# S32R372 register map
Vendor: Freescale Semiconductor, Inc.; Series: Qorivva; File version: 1.6
Registers are 32-bit, read-write, reset 0x0 unless marked. A register's access mark holds for its fields unless they carry their own. Offsets are from the block's base; [hi:lo] are bit positions; {n}, {i} and the like mark numbered series.

## MIPICSI2 — Camera Serial Interface
Base 0xFBF08000; register names take the prefix MIPICSI2_
0x00 CONC — RX Controller Configuration Register
  [0] NULANE — Number of active lanes being used to receive MIPICSI2 data
    0=1 lane; 1=2 Lanes
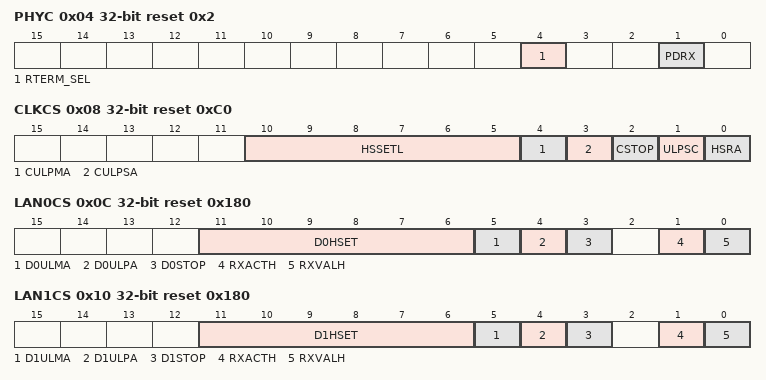
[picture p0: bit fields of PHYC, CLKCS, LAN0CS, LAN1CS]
0x04 PHYC reset 0x2 — PHY Configuration Register
  [4] RTERM_SEL — Voltage Level selection for HS termination
    0=Low Power Receive level enables High Speed Termination; 1=Low Power Contention Detector level enables High Speed Termination
  [1] PDRX — Power Down Receiver
    0=Power down disabled; 1=Power down enabled for all blocks inside PHY
0x08 CLKCS reset 0xC0 — Clock Configuration Status Register
  [10:5] HSSETL — Clock Lane Program RX HS Settle
  [4] CULPMA ro — Clock Lane ULPS mark Active State
    0=Clock Lane not in Mark active state; 1=Clock Lane is in mark active state
  [3] CULPSA ro — Clock Lane ULPS Active
    0=Clock Lane not in ULPS mode; 1=Clock Lane in ULPS mode
  [2] CSTOP ro — Clock Lane Stop State
    0=Clock Lane not in stop state; 1=Clock Lane in stop state
  [1] ULPSC ro — Clock Lane ULPS
    0=Clock lane not in ultra low power state; 1=Clock Lane in ultra low power state
  [0] HSRA ro — High Speed Clock Receive Active
    0=DDR clock not being received on the clock lane currently; 1=Clock lane is receiving DDR clock
0x0C LAN0CS reset 0x180 — D-PHY Lane 0 Configuration Status Register
  [11:6] D0HSET — Data lane 0 Program RX HS Settle time
  [5] D0ULMA ro — Data Lane 0 ULPS Mark Active
    0=Data lane 0 is not in Mark 1 state; 1=Data lane 0 is in mark 1 state
  [4] D0ULPA ro — Data lane 0 ULPS Active
    0=Data Lane 0 ULPS not active; 1=Data lane 0 ULPS Active
  [3] D0STOP ro — Data Lane 0 Stop State
    0=Data lane 0 not in stop state; 1=Data lane 0 in stop state
  [1] RXACTH ro — D-PHY Data lane 0 RX active High Speed data
    0=No High Speed data reception ongoing from the lane interconnect; 1=High speed data reception ongoing from lane interconnect
  [0] RXVALH ro — Data Lane 0 RX Valid HS
    0=No Valid High Speed data being driven from data lane 0 to MIPICSI2 RX controller; 1=Valid High Speed data being driven from data lane 0 to MIPICSI2 RX Controller
0x10 LAN1CS reset 0x180 — D-PHY Data LANE 1 Configuration Status Register
  [11:6] D1HSET — D_PHY Data Lane 1 PRG HS Settle time
  [5] D1ULMA ro — D_PHY Data Lane 1 ULPS Mark active
    0=Data Lane 1 not in ULPS mark active state; 1=Data Lane 1 in ULPS Mark Active state
  [4] D1ULPA ro — D-PHY Data Lane 1 ULPS Active
    0=Data lane not in ULPS state; 1=Data Lane 1 in ULPS state
  [3] D1STOP ro — D-PHY Data Lane 1 Stop
    0=Data lane 1 is not in stop state; 1=Data lane 1 is in stop state
  [1] RXACTH ro — D-PHY Data lane 1 Active HS
    0=Data lane 1 not receiving high speed active data on the lane interconnect; 1=Data Lane 1 receiving active high speed data on the lane interconnect
  [0] RXVALH ro — D-PHY Data lane 1 Receive Valid High speed
    0=No Valid High speed data being driven from data lane 1 to the MIPICSI2 RX controller; 1=Valid HS data being transmitted from data lane 1 to the MIPICSI2 RX controller
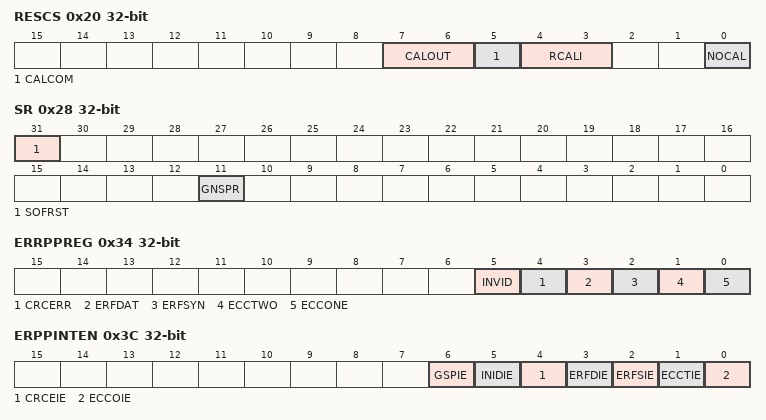
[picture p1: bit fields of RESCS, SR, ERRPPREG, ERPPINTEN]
0x20 RESCS — External Resistor Configuration Status Register
  [7:6] CALOUT ro — Calibrator output
  [5] CALCOM ro — Calibration Complete
    0=Calibration incomplete; 1=Calibration Complete
  [4:3] RCALI — Resistor Calibration Input
  [0] NOCAL — No Calibration
    0=Auto Calibration; 1=No auto Calibration, manual calibration
0x28 SR — Status Register
  [31] SOFRST — Software reset
    0=No soft reset requested; 1=Soft Reset requested by Software. When set it causes a reset of all the registers and all the FIFOs will be flushed.
  [11] GNSPR — Generic Short Packet Received
    0=No generic short packet field was received; 1=Generic Short Packet field was received
0x2C DATAID ro — DataID Report Register
  [5:0] DATIDF — Data ID Field
    0=Frame start; 1=Frame end; 2=Line start; 3=Line end; 16=Null data; 17=Blanking data; 30=YUV 422 - 8bit data; 31=YUV 422 10 bit data; 34=RGB565 data; 36=RGB888 data; 42=RAW8 data; 43=RAW10 data; 44=RAW12 data; 45=RAW14 data; 18=Embedded data
0x34 ERRPPREG — Protocol and Packet Error Register
  [5] INVID — Invalid ID
  [4] CRCERR — CRC Error
  [3] ERFDAT — Frame data error
  [2] ERFSYN — Frame synchronization error
  [1] ECCTWO — ECC Two Bit Error
  [0] ECCONE — ECC one bit error
0x38 ERRPOS ro — Error Position
  [4:0] ERRPOS
0x3C ERPPINTEN — Protocol Packet Error Interrupt Enable
  [6] GSPIE — Generic Short Packet Interrupt Enable
    0=Interrupt on generic short packet reception disabled; 1=Interrupt on generic short packet reception enabled
  [5] INIDIE — Invalid ID Error Interrupt Enable
    0=Interrupt on invalid ID error disabled; 1=Interrupt on Invalid ID error enabled
  [4] CRCEIE — CRC Error Interrupt Enable
    0=Interrupt on CRC error disabled; 1=Interrupt on CRC error enabled
  [3] ERFDIE — Error Frame Data Interrupt Enable
    0=Interrupt on frame data error disabled; 1=Interrupt on frame data error enabled
  [2] ERFSIE — Frame Synchronization Error Interrupt Enable
    0=Interrupt on frame Synchronization error disabled; 1=Interrupt on frame Synchronization error enabled
  [1] ECCTIE — ECC Two Interrupt Enable
    0=Interrupt on ECC two bit error disabled; 1=Interrupt on ECC two bit error enabled
  [0] ECCOIE — ECC One Interrupt Enable
    0=Interrupt on ECC one bit error disabled; 1=Interrupt on ECC one bit error enabled
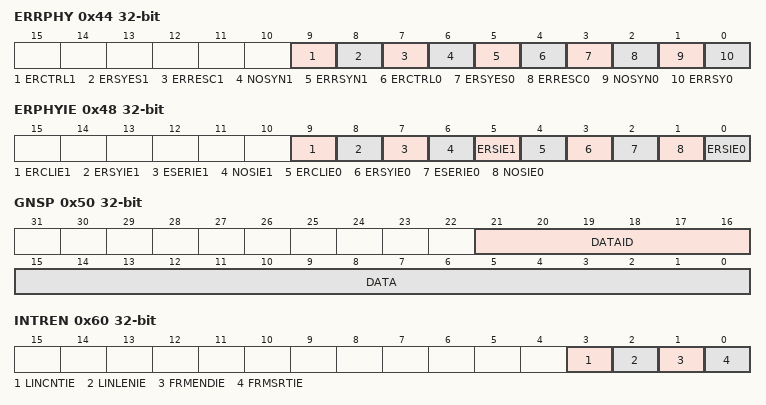
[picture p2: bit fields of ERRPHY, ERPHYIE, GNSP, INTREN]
0x44 ERRPHY — PHY Error Report Register
  [9] ERCTRL1 — Control Error on lane 1
  [8] ERSYES1 — Synchronization error in Escape mode on lane 1
  [7] ERRESC1 — Escape Mode Entry Error on lane 1
  [6] NOSYN1 — No Synchronization Error Lane 1
  [5] ERRSYN1 — Error in the synchronization pattern detected by PHY in lane1
  [4] ERCTRL0 — Control Error on lane 0
  [3] ERSYES0 — Synchronization error in Escape mode on lane 0
  [2] ERRESC0 — Escape Mode Entry Error on lane 0
  [1] NOSYN0 — No Synchronization Error Lane 0 on HS entry
  [0] ERRSY0 — Error in the synchronization pattern detected by PHY in lane0
0x48 ERPHYIE — Phy Error Interrupt Enable Register
  [9] ERCLIE1 — This field allows interrupt to be enabled when an incorrect line state sequence transition has been observed
    0=Interrupt disabled on control errors encountered on lane 3; 1=Interrupt enabled on control errors encountered on lane 3
  [8] ERSYIE1 — This field is used to enable the interrupt when a synchronization error is observed in the escape mode
    0=interrupt disabled on Synchronization errors in escape mode on lane1; 1=interrupt enabled on Synchronization errors in escape mode on lane1
  [7] ESERIE1 — This field is used for enabling interrupt on detection of an escape mode entry error
    0=Interrupt disabled on escape mode entry error on lane 1; 1=Interrupt enabled on escape mode entry error on lane 1
  [6] NOSIE1 — This field enables interrupt generation when the NOSYN1 field in the error register is set
    0=Interrupt disabled on multibit errors in Synchronization error on lane 1; 1=Interrupt enabled on multibit errors in Synchronization error on lane 1
  [5] ERSIE1 — This field enables interrupt generation when the ERSYN1 field in the error register is set
    0=Interrupt on One bit Synchronization error in sync pattern on high speed entry on lane 1 disabled; 1=Interrupt on One bit Synchronization error in sync pattern on high speed entry on lane 1 enabled
  [4] ERCLIE0 — This field allows interrupt to be enabled when an incorrect line state sequence transition has been observed
    0=Interrupt disabled on control errors encountered on lane 0; 1=Interrupt enabled on control errors encountered on lane 0
  [3] ERSYIE0 — This field is used to enable the interrupt when a synchronization error is observed in the escape mode
    0=interrupt disabled on Synchronization errors in escape mode on lane0; 1=interrupt enabled on Synchronization errors in escape mode on lane0
  [2] ESERIE0 — This field is used for enabling interrupt on detection of an escape mode entry error
    0=Interrupt disabled on escape mode entry error; 1=Interrupt enabled on escape mode entry error
  [1] NOSIE0 — This field enables interrupt generation when the NOSYN0 field in the error register is set
    0=Interrupt disabled on multibit errors in Synchronization error on lane 0; 1=Interrupt enabled on multibit errors in Synchronization error on lane 0
  [0] ERSIE0 — This field enables interrupt generation when the ERSYN0 field in the error register is set
    0=Interrupt on One bit Synchronization error in sync pattern on high speed entry on lane 0 disabled; 1=Interrupt on One bit Synchronization error in sync pattern on high speed entry on lane 0 enabled
0x4C RXEN — RX Enable Register
  [0] RXEN — Receive enable
    0=RX disabled; 1=RX enabled
0x50 GNSP ro — Generic Short Packet Data Register
  [21:16] DATAID — Data type
    {v}=Generic short packet code {v-7} (v=8..15)
  [15:0] DATA — Data field of a generic short packet
0x54 INVID ro — Invalid ID Report Register
  [5:0] INVID — Invalid ID
0x58 LINLEN — LINE LENGTH
  [15:0] LINLEN
0x5C EXPCTDL — Expected Number of Lines
  [15:0] EXPLINES — Expected Number Of Lines In a Frame
0x60 INTREN — Interrupt Enable
  [3] LINCNTIE — Line Count Error Interrupt Enable
    0=Interrupt on Line Count Error disabled; 1=Interrupt on Line Count Error enabled
  [2] LINLENIE — Line Length Error Interrupt Enable
    0=Interrupt on Line Length Error Disabled; 1=Interrupt on Line Length Error enabled
  [1] FRMENDIE — Frame End Detection Interrupt Enable
    0=Interrupt on frame end indication disabled; 1=Interrupt on frame end indication enabled
  [0] FRMSRTIE — Frame Start Detected Interrupt Enable
    0=Interrupt on frame start indication disabled; 1=Interrupt on frame start indication Enabled
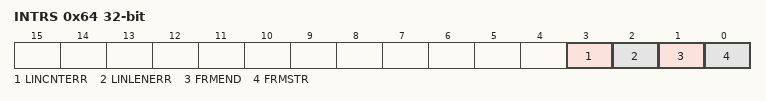
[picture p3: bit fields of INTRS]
0x64 INTRS — Interrupt Status
  [3] LINCNTERR — Line Count Error Indication
    0=No Error in line count detected or error cleared; 1=Error in line count detected
  [2] LINLENERR — Line Length Error Indication
    0=No error in line length detected or error cleared; 1=Error in line length detected
  [1] FRMEND — Frame End Indication
    0=Frame End not detected or indication cleared; 1=Frame End detected
  [0] FRMSTR — Frame Start Indication
    0=Frame Start not detected or indication cleared; 1=Frame Start detected
